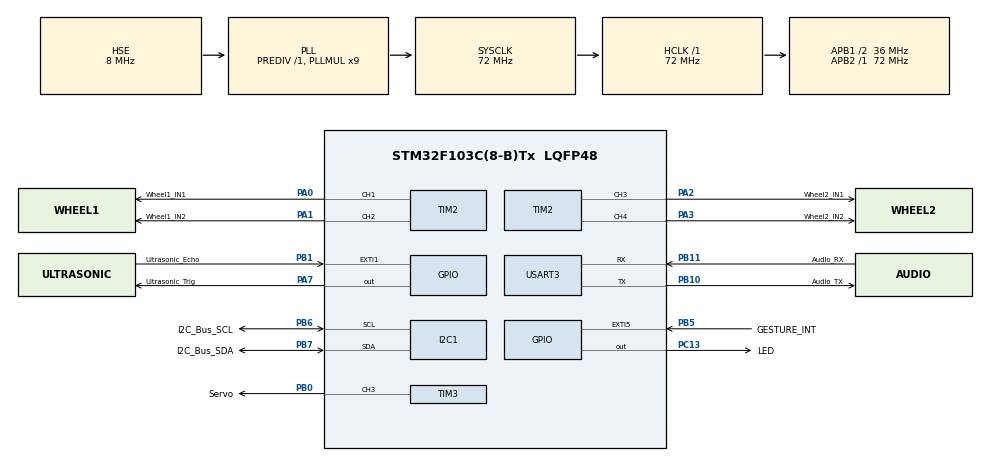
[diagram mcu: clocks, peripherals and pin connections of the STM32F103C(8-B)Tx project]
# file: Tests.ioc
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Mcu.Family=STM32F1
Mcu.Name=STM32F103C(8-B)Tx
Mcu.Package=LQFP48
NVIC.EXTI1_IRQn=true\:0\:0\:false\:false\:true\:true\:true\:true
NVIC.EXTI9_5_IRQn=true\:0\:0\:false\:false\:true\:true\:true\:true
NVIC.PriorityGroup=NVIC_PRIORITYGROUP_4
NVIC.TIM4_IRQn=true\:0\:0\:false\:false\:true\:true\:true\:true
NVIC.USART3_IRQn=true\:0\:0\:false\:false\:true\:true\:true\:true
PA0-WKUP.GPIO_Label=Wheel1_IN1
PA0-WKUP.GPIO_Speed=GPIO_SPEED_FREQ_HIGH
PA0-WKUP.Signal=S_TIM2_CH1_ETR
PA1.GPIO_Label=Wheel1_IN2
PA1.GPIO_Speed=GPIO_SPEED_FREQ_HIGH
PA1.Signal=S_TIM2_CH2
PA13.Mode=Serial_Wire
PA13.Signal=SYS_JTMS-SWDIO
PA14.Mode=Serial_Wire
PA14.Signal=SYS_JTCK-SWCLK
PA2.GPIO_Label=Wheel2_IN1
PA2.GPIO_Speed=GPIO_SPEED_FREQ_HIGH
PA2.Signal=S_TIM2_CH3
PA3.GPIO_Label=Wheel2_IN2
PA3.GPIO_Speed=GPIO_SPEED_FREQ_HIGH
PA3.Signal=S_TIM2_CH4
PA7.GPIO_Label=Ultrasonic_Trig
PA7.GPIO_PuPd=GPIO_PULLDOWN
PA7.GPIO_Speed=GPIO_SPEED_FREQ_HIGH
PA7.Signal=GPIO_Output
PB0.GPIO_Label=Servo
PB0.GPIO_Speed=GPIO_SPEED_FREQ_HIGH
PB0.Signal=S_TIM3_CH3
PB1.GPIO_Label=Ultrasonic_Echo
PB1.GPIO_ModeDefaultEXTI=GPIO_MODE_IT_RISING_FALLING
PB1.GPIO_PuPd=GPIO_PULLDOWN
PB1.Signal=GPXTI1
PB10.GPIO_Label=Audio_TX
PB10.Mode=Asynchronous
PB10.Signal=USART3_TX
PB11.GPIO_Label=Audio_RX
PB11.Mode=Asynchronous
PB11.Signal=USART3_RX
PB5.GPIO_Label=GESTURE_INT
PB5.GPIO_ModeDefaultEXTI=GPIO_MODE_IT_FALLING
PB5.GPIO_PuPd=GPIO_PULLUP
PB5.Signal=GPXTI5
PB6.GPIO_Label=I2C_Bus_SCL
PB6.Mode=I2C
PB6.Signal=I2C1_SCL
PB7.GPIO_Label=I2C_Bus_SDA
PB7.Mode=I2C
PB7.Signal=I2C1_SDA
PC13-TAMPER-RTC.GPIO_Label=LED
PC13-TAMPER-RTC.GPIO_Speed=GPIO_SPEED_FREQ_LOW
PC13-TAMPER-RTC.Signal=GPIO_Output
PC14-OSC32_IN.Mode=LSE-External-Oscillator
PC14-OSC32_IN.Signal=RCC_OSC32_IN
PC15-OSC32_OUT.Mode=LSE-External-Oscillator
PC15-OSC32_OUT.Signal=RCC_OSC32_OUT
PD0-OSC_IN.Mode=HSE-External-Oscillator
PD0-OSC_IN.Signal=RCC_OSC_IN
PD1-OSC_OUT.Mode=HSE-External-Oscillator
PD1-OSC_OUT.Signal=RCC_OSC_OUT
ProjectManager.HeapSize=0x200
ProjectManager.StackSize=0x400
ProjectManager.TargetToolchain=MDK-ARM V5.32
RCC.AHBFreq_Value=72000000
RCC.APB1CLKDivider=RCC_HCLK_DIV2
RCC.APB1Freq_Value=36000000
RCC.APB1TimFreq_Value=72000000
RCC.APB2Freq_Value=72000000
RCC.APB2TimFreq_Value=72000000
RCC.HCLKFreq_Value=72000000
RCC.PLLMUL=RCC_PLL_MUL9
RCC.PLLSourceVirtual=RCC_PLLSOURCE_HSE
RCC.SYSCLKFreq_VALUE=72000000
RCC.SYSCLKSource=RCC_SYSCLKSOURCE_PLLCLK
RCC.USBFreq_Value=72000000
SH.S_TIM2_CH1_ETR.0=TIM2_CH1,PWM Generation1 CH1
SH.S_TIM2_CH2.0=TIM2_CH2,PWM Generation2 CH2
SH.S_TIM2_CH3.0=TIM2_CH3,PWM Generation3 CH3
SH.S_TIM2_CH4.0=TIM2_CH4,PWM Generation4 CH4
SH.S_TIM3_CH3.0=TIM3_CH3,PWM Generation3 CH3
TIM2.Channel-PWM\ Generation1\ CH1=TIM_CHANNEL_1
TIM2.Channel-PWM\ Generation2\ CH2=TIM_CHANNEL_2
TIM2.Channel-PWM\ Generation3\ CH3=TIM_CHANNEL_3
TIM2.Channel-PWM\ Generation4\ CH4=TIM_CHANNEL_4
TIM3.Channel-PWM\ Generation3\ CH3=TIM_CHANNEL_3
TIM3.Period=200-1
TIM3.Prescaler=7200-1
TIM4.AutoReloadPreload=TIM_AUTORELOAD_PRELOAD_ENABLE
TIM4.Prescaler=720-1
USART3.VirtualMode=VM_ASYNC
VP_TIM4_VS_ClockSourceINT.Mode=Internal
board=custom

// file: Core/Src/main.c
/* USER CODE BEGIN Header */
/**
  ******************************************************************************
  * @file           : main.c
  * @brief          : Main program body
  ******************************************************************************
  * @attention
  *
  * Copyright (c) 2025 STMicroelectronics.
  * All rights reserved.
  *
  * This software is licensed under terms that can be found in the LICENSE file
  * in the root directory of this software component.
  * If no LICENSE file comes with this software, it is provided AS-IS.
  *
  ******************************************************************************
  */
/* USER CODE END Header */
#include "main.h"
#include "i2c.h"
#include "tim.h"
#include "usart.h"
#include "gpio.h"

/* USER CODE BEGIN Includes */
#include "blinking.h"
#include "display.h"
#include "following.h"
#include "tail.h"
#include "gesture.h"
/* USER CODE END Includes */

void SystemClock_Config(void);

int main(void)
{

  /* MCU Configuration--------------------------------------------------------*/

  /* Reset of all peripherals, Initializes the Flash interface and the Systick. */
  HAL_Init();

  /* Configure the system clock */
  SystemClock_Config();

  /* Initialize all configured peripherals */
  MX_GPIO_Init();
  MX_I2C1_Init();
  MX_TIM2_Init();
  MX_USART3_UART_Init();
  MX_TIM3_Init();
  MX_TIM4_Init();
  /* USER CODE BEGIN 2 */
  //app_blinking_task_demo();
  //app_display_test_demo();
  //app_following_test_demo();
  //app_tail_test_demo();
  app_gesture_test_demo();
  /* USER CODE END 2 */

  /* Infinite loop */
  while (1)
  {

  }
}

void SystemClock_Config(void)
{
  RCC_OscInitTypeDef RCC_OscInitStruct = {0};
  RCC_ClkInitTypeDef RCC_ClkInitStruct = {0};

  /** Initializes the RCC Oscillators according to the specified parameters
  * in the RCC_OscInitTypeDef structure.
  */
  RCC_OscInitStruct.OscillatorType = RCC_OSCILLATORTYPE_HSE;
  RCC_OscInitStruct.HSEState = RCC_HSE_ON;
  RCC_OscInitStruct.HSEPredivValue = RCC_HSE_PREDIV_DIV1;
  RCC_OscInitStruct.HSIState = RCC_HSI_ON;
  RCC_OscInitStruct.PLL.PLLState = RCC_PLL_ON;
  RCC_OscInitStruct.PLL.PLLSource = RCC_PLLSOURCE_HSE;
  RCC_OscInitStruct.PLL.PLLMUL = RCC_PLL_MUL9;
  if (HAL_RCC_OscConfig(&RCC_OscInitStruct) != HAL_OK)
  {
    Error_Handler();
  }

  /** Initializes the CPU, AHB and APB buses clocks
  */
  RCC_ClkInitStruct.ClockType = RCC_CLOCKTYPE_HCLK|RCC_CLOCKTYPE_SYSCLK
                              |RCC_CLOCKTYPE_PCLK1|RCC_CLOCKTYPE_PCLK2;
  RCC_ClkInitStruct.SYSCLKSource = RCC_SYSCLKSOURCE_PLLCLK;
  RCC_ClkInitStruct.AHBCLKDivider = RCC_SYSCLK_DIV1;
  RCC_ClkInitStruct.APB1CLKDivider = RCC_HCLK_DIV2;
  RCC_ClkInitStruct.APB2CLKDivider = RCC_HCLK_DIV1;

  if (HAL_RCC_ClockConfig(&RCC_ClkInitStruct, FLASH_LATENCY_2) != HAL_OK)
  {
    Error_Handler();
  }
}

void Error_Handler(void)
{
  __disable_irq();
  while (1)
  {
  }
}
